# PY32MD410xx register map
Vendor: Puya; Series: PY32M; File version: 1.0.0
CPU: CM0+ r0p1, little endian, no MPU, no FPU, 4 interrupt priority bits
Registers are 32-bit, read-write, reset 0x0 unless marked. A register's access mark holds for its fields unless they carry their own. Offsets are from the block's base; [hi:lo] are bit positions; {n}, {i} and the like mark numbered series.

## LCD — LCD CONTROLLER
Base 0x40002400
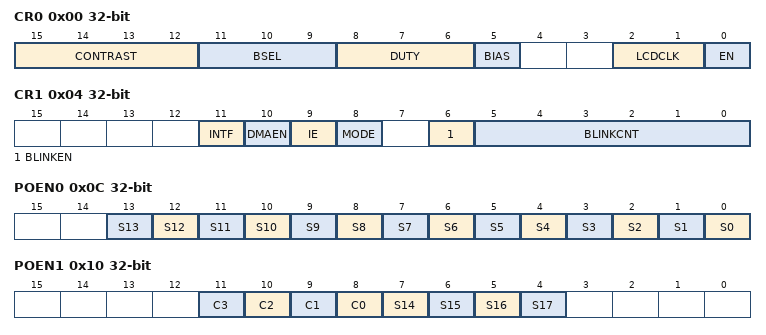
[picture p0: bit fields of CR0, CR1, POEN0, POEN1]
0x00 CR0 — Control register
  [15:12] CONTRAST, [11:9] BSEL, [8:6] DUTY, [5] BIAS, [2:1] LCDCLK, [0] EN
0x04 CR1
  [11] INTF, [10] DMAEN, [9] IE, [8] MODE, [6] BLINKEN, [5:0] BLINKCNT
0x08 INTCLR
  [10] INTF_CLR
0x0C POEN0
  [n] S{n} (n=0..13)
0x10 POEN1
  [n+8] C{n} (n=0..3), [21-n] S{n} (n=14..17)
{0x14+4i} RAM{i} (i=0..3) — des RAM{i}
  [31:0] D — des D
0x24 RAM4 — des RAM4
  [15:0] D — des D

## LPTIM — Low power timer
Base 0x40007C00
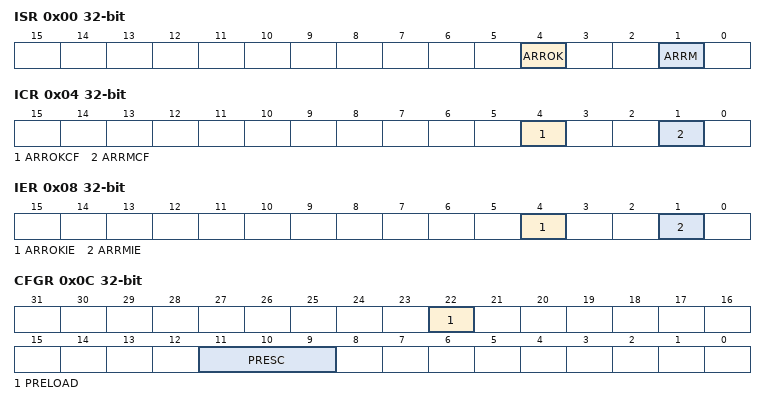
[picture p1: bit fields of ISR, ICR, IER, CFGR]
0x00 ISR ro — Interrupt and Status Register
  [4] ARROK — Autoreload OK
  [1] ARRM — Autoreload match
0x04 ICR wo — Interrupt Clear Register
  [4] ARROKCF — Autoreload OK Clear Flag
  [1] ARRMCF — Autoreload match Clear Flag
0x08 IER — Interrupt Enable Register
  [4] ARROKIE — Autoreload OK Interrupt Enable
  [1] ARRMIE — Autoreload match Interrupt Enable
0x0C CFGR — Configuration Register
  [22] PRELOAD — Registers update mode
  [11:9] PRESC — Clock prescaler
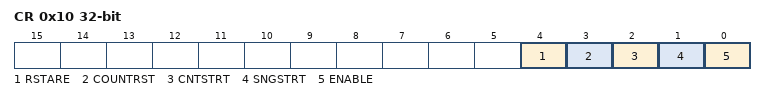
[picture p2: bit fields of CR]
0x10 CR — Control Register
  [4] RSTARE — Reset after read enable
  [3] COUNTRST — LPTIM counter reset
  [2] CNTSTRT — LPTIM start in continue mode
  [1] SNGSTRT — LPTIM start in single mode
  [0] ENABLE — LPTIM Enable
0x18 ARR reset 0x1 — Autoreload Register
  [15:0] ARR — Auto reload value
0x1C CNT ro — Counter Register
  [15:0] CNT — Counter value

## OPA — Operational amplifier
Base 0x40010300
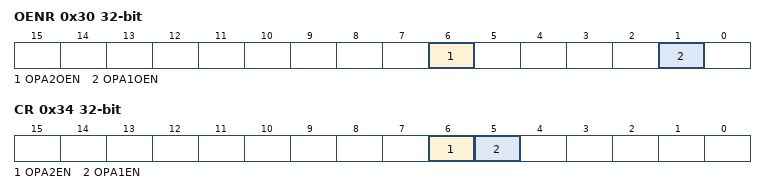
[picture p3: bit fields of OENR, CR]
0x30 OENR — OPA output enable register
  [6] OPA2OEN — OPA2 output enable
  [1] OPA1OEN — OPA1 output enable
0x34 CR — OPA control register
  [6] OPA2EN — OPA2 enable
  [5] OPA1EN — OPA1 enable

## PWR — Power control
Base 0x40007000
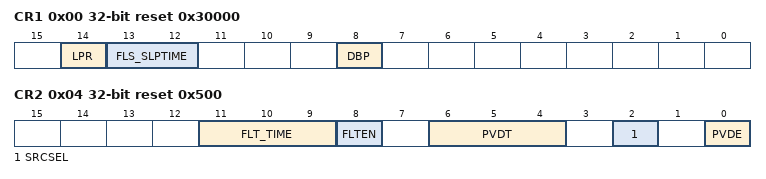
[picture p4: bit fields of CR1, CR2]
0x00 CR1 reset 0x30000 — Power control register 1
  [14] LPR — Low-power run
  [13:12] FLS_SLPTIME — Flash wait time after wakeup from the stop mode
  [8] DBP — Disable backup domain write protection
0x04 CR2 reset 0x500 — Power control register 2
  [11:9] FLT_TIME — Digital filter time configuration
  [8] FLTEN — Digital filter enable
  [6:4] PVDT — Power voltage detector threshold selection
  [2] SRCSEL — Power voltage detector volatage selection
  [0] PVDE — Power voltage detector enable
0x14 SR ro — Power status register
  [11] PVDO — PVD output

## RTC — Real time clock
Base 0x40002800
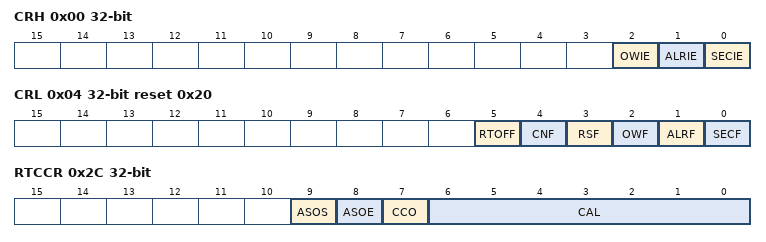
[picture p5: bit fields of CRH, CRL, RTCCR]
0x00 CRH — RTC Control Register High
  [2] OWIE — Overflow interrupt Enable
  [1] ALRIE — Alarm interrupt Enable
  [0] SECIE — Second interrupt Enable
0x04 CRL reset 0x20 — RTC Control Register Low
  [5] RTOFF ro — RTC operation OFF
  [4] CNF — Configuration Flag
  [3] RSF — Registers Synchronized Flag
  [2] OWF — Overflow Flag
  [1] ALRF — Alarm Flag
  [0] SECF — Second Flag
0x08 PRLH wo — RTC Prescaler Load Register High
  [3:0] PRLH
0x0C PRLL wo reset 0x8000 — RTC Prescaler Load Register Low
  [15:0] PRLL — RTC Prescaler Divider Register Low
0x10 DIVH ro — RTC Prescaler Divider Register High
  [3:0] DIVH — RTC prescaler divider register high
0x14 DIVL ro reset 0x8000 — RTC Prescaler Divider Register Low
  [15:0] DIVL — RTC prescaler divider register Low
0x18 CNTH — RTC Counter Register High
  [15:0] CNTH — RTC counter register high
0x1C CNTL — RTC Counter Register Low
  [15:0] CNTL — RTC counter register Low
0x20 ALRH reset 0xFFFF — RTC Alarm Register High
  [15:0] ALRH — RTC alarm register high
0x24 ALRL reset 0xFFFF — RTC Alarm Register Low
  [15:0] ALRL — RTC alarm register low
0x2C RTCCR — RTC clock calibration
  [9] ASOS — Alarm or second output selection
  [8] ASOE — Alarm or second output enable
  [7] CCO — Calibration clock output
  [6:0] CAL — Calibration value

## SPI1 — Serial peripheral interface
Base 0x40013000
Same registers: SPI2 0x40003800
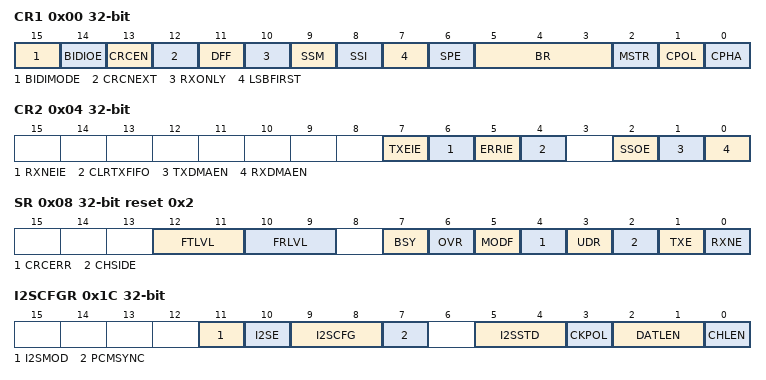
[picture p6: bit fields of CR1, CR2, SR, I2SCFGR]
0x00 CR1 — control register 1
  [15] BIDIMODE — Bidirectional data mode enable
  [14] BIDIOE — Output enable in bidirectional mode
  [13] CRCEN — Hardware CRC calculation enable
  [12] CRCNEXT — Transmit CRC next
  [11] DFF — Data frame format
  [10] RXONLY — Receive only
  [9] SSM — Software slave management
  [8] SSI — Internal slave selection
  [7] LSBFIRST — Frame format
  [6] SPE — SPI enable
  [5:3] BR — Baud rate control
  [2] MSTR — Master selection
  [1] CPOL — Clock polarity
  [0] CPHA — Clock phase
0x04 CR2 — control register 2
  [7] TXEIE — Tx buffer empty interrupt enable
  [6] RXNEIE — RX buffer not empty interrupt enable
  [5] ERRIE — Error interrupt enable
  [4] CLRTXFIFO — Clear TXFIFO
  [2] SSOE — SS output enable
  [1] TXDMAEN — Tx buffer DMA enable
  [0] RXDMAEN — Rx buffer DMA enable
0x08 SR reset 0x2 — status register
  [12:11] FTLVL ro — FIFO transmission level
  [10:9] FRLVL ro — FIFO reception level
  [7] BSY ro — Busy flag
  [6] OVR ro — Overrun flag
  [5] MODF ro — Mode fault
  [4] CRCERR ro — CRC error flag
  [3] UDR ro — Underflow flag
  [2] CHSIDE ro — Channel control
  [1] TXE ro — Transmit buffer empty
  [0] RXNE ro — Receive buffer not empty
0x0C DR — data register
  [15:0] DR — Data register
0x10 CRCPR — CRC polynomial register
  [15:0] CRCPOLY
0x14 RXCRC
  [15:0] RXCRC
0x18 TXCRC
  [15:0] TXCRC
0x1C I2SCFGR — I2S Configuration register
  [11] I2SMOD — I2S mode selection
  [10] I2SE — I2S enable
  [9:8] I2SCFG — I2S configuration mode
  [7] PCMSYNC — PCM frame synchronization
  [5:4] I2SSTD — I2S standard selection
  [3] CKPOL — Steady state clock polarity
  [2:1] DATLEN — Data length to be transferred
  [0] CHLEN — Channel length
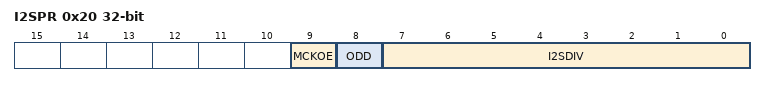
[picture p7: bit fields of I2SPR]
0x20 I2SPR — I2S prescaler register
  [9] MCKOE — Master clock output enable
  [8] ODD — Odd factor for the prescaler
  [7:0] I2SDIV — I2S linear prescaler
